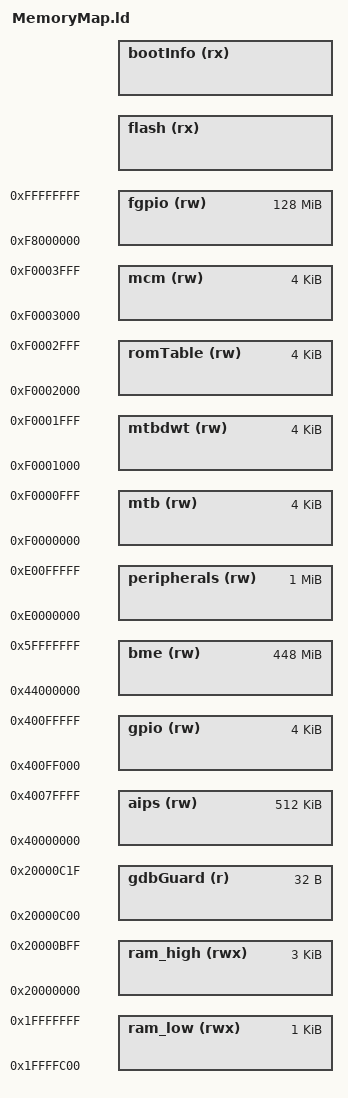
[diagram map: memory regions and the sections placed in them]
/* MemoryMap.ld (Packages\100.ARM_DeviceOptions\Project_Settings\Linker_Files)
 *
 * Memory map for devices without SRAM_U allocation for bit-band/bme
 */
 
/* ---- <<< Use Configuration Wizard in Context Menu >>> ---- */

/* <o> Stack Size
   <i> Required amount of stack space
   <i> In CMSIS this will determine the ISR stack size
   <0x0-0xC00:4> 
*/
__stack_size = 0x600;

/* <o> Minimum Heap Size 
   <i> This is the minimum allocated.  
   <i> Available heap may be larger.
   <0x0-0xC00:4> 
*/
__heap_size  = 0x200;
   
/*
 <e1> Enable Bootloader
 <i>  Enable custom USBDM bootloader
*/
FORCE_BOOT_LOADER = DEFINED(bootInformation) ? 1 : 0;
/*
    <o>  Bootloader size (usually 0x4000 if used) <constant>
    <i>  The bootloader is located at the bottom of the flash region
    <i>  This value is used to automatically adjust the available flash area 
 */
BOOT_LOADER_SIZE  = DEFINED(BOOT_LOADER_SIZE)  ? BOOT_LOADER_SIZE : 0x4000 * FORCE_BOOT_LOADER;
/*
    <o>  Bootloader information block size (usually 0x10 if used) <constant>
    <i>  The bootloader information block is located at the top of the flash region
    <i>  This value is used to automatically adjust the available flash area 
 */
BOOT_INFO_SIZE    = DEFINED(BOOT_INFO_SIZE)    ? BOOT_INFO_SIZE   : 0x10 * (BOOT_LOADER_SIZE > 0);
/* </e> */

/*
 * Memory Map generated by USBDM New Project Wizard for FRDM_KL05Z
 */
 
MEMORY
{
  aips           (rw)  : ORIGIN = 0x40000000, LENGTH = 0x00080000
  gpio           (rw)  : ORIGIN = 0x400FF000, LENGTH = 0x00001000
  bme            (rw)  : ORIGIN = 0x44000000, LENGTH = 0x1C000000
  peripherals    (rw)  : ORIGIN = 0xE0000000, LENGTH = 0x00100000
  mtb            (rw)  : ORIGIN = 0xF0000000, LENGTH = 0x00001000
  mtbdwt         (rw)  : ORIGIN = 0xF0001000, LENGTH = 0x00001000
  romTable       (rw)  : ORIGIN = 0xF0002000, LENGTH = 0x00001000
  mcm            (rw)  : ORIGIN = 0xF0003000, LENGTH = 0x00001000
  fgpio          (rw)  : ORIGIN = 0xF8000000, LENGTH = 0x08000000
/*
    <o>  FLASH  address <constant>
    <o1> FLASH  size    <constant>
 */
  flash          (rx)  : ORIGIN = 0x00000000 + BOOT_LOADER_SIZE, LENGTH = 0x00008000 - BOOT_LOADER_SIZE - BOOT_INFO_SIZE
  bootInfo       (rx)  : ORIGIN = 0x00008000 - BOOT_INFO_SIZE,   LENGTH = BOOT_INFO_SIZE
/*
    <o>  ram_high address <constant>
    <o1> ram_high size    <constant>
 */
  ram_high       (rwx) : ORIGIN = 0x20000000, LENGTH = 0x00000C00
/*
    <o>  ram_low address <constant>
    <o1> ram_low size    <constant>
 */
  ram_low        (rwx) : ORIGIN = 0x1FFFFC00, LENGTH = 0x00000400
/*
 * Guard region above stack for GDB 
 */
  gdbGuard       (r)   : ORIGIN = 0x20000C00, LENGTH = 0x00000020
};

REGION_ALIAS("ram","ram_high");


/*
  <h> Section placement in RAM
  <i> The RAM on Cortex-M4 Kinetis devices is divided into upper and lower memory regions.
  <i> These settings control which region is used for various linker sections.
  <i> These sections cannot cross regions as unaligned half-word and long-word accesses are not supported.
*/
/*  <s1>  Micro Trace Buffer                <"ram_low"=> ram_low <"ram_high"=> ram_high <i> mtb_ram        */
REGION_ALIAS("mtb_ram", 	   "ram_low");
/*  <s1>  Vector table relocated to RAM     <"ram_low"=> ram_low <"ram_high"=> ram_high <i> interrupts_ram */
REGION_ALIAS("interrupts_ram", "ram_low");
/*  <s1>  USB Endpoint buffers              <"ram_low"=> ram_low <"ram_high"=> ram_high <i> bdts_ram       */
REGION_ALIAS("bdts_ram",       "ram_low");
/*  <s1>  Initialised DATA                  <"ram_low"=> ram_low <"ram_high"=> ram_high <i> data_ram       */
REGION_ALIAS("data_ram",       "ram_low");
/*  <s1>  Non-initialised DATA              <"ram_low"=> ram_low <"ram_high"=> ram_high <i> noinit_ram     */
REGION_ALIAS("noinit_ram",     "ram_low");
/*  <s1>  Zeroed Data (BSS)                 <"ram_low"=> ram_low <"ram_high"=> ram_high <i> bss_ram        */
REGION_ALIAS("bss_ram",        "ram_low");
/*  <s1>  Heap                              <"ram_low"=> ram_low <"ram_high"=> ram_high <i> heap_ram       */
REGION_ALIAS("heap_ram",       "ram_high");
/*  <s1>  Stack                             <"ram_low"=> ram_low <"ram_high"=> ram_high <i> stack_ram      */
REGION_ALIAS("stack_ram",      "ram_high");
/* </h> */

/* These must be in upper RAM */
REGION_ALIAS("sram_u_ram",     "ram_high");
REGION_ALIAS("bitband_ram",    "ram_high");

INCLUDE Linker-rom.ld

